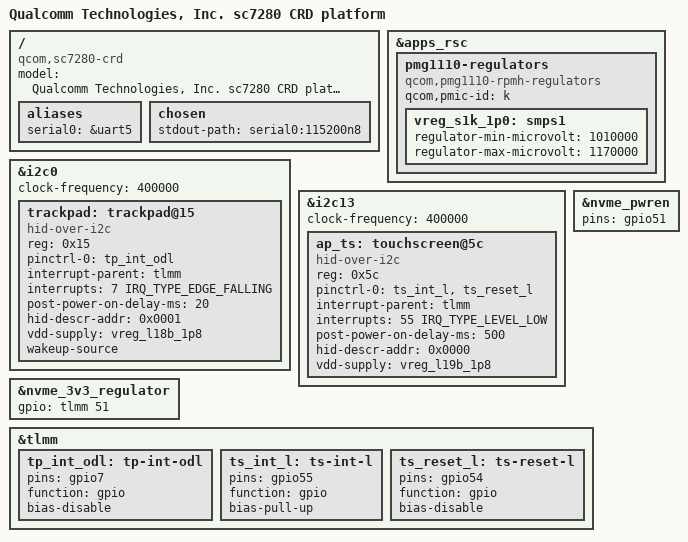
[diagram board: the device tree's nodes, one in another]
// SPDX-License-Identifier: BSD-3-Clause
/*
 * sc7280 CRD board device tree source
 *
 * Copyright (c) 2021 Qualcomm Innovation Center, Inc. All rights reserved.
 */

/dts-v1/;

#include "sc7280-idp.dtsi"
#include "sc7280-idp-ec-h1.dtsi"

/ {
	model = "Qualcomm Technologies, Inc. sc7280 CRD platform";
	compatible = "qcom,sc7280-crd", "google,hoglin", "qcom,sc7280";

	aliases {
		serial0 = &uart5;
	};

	chosen {
		stdout-path = "serial0:115200n8";
	};
};

&apps_rsc {
	pmg1110-regulators {
		compatible = "qcom,pmg1110-rpmh-regulators";
		qcom,pmic-id = "k";

		vreg_s1k_1p0: smps1 {
			regulator-min-microvolt = <1010000>;
			regulator-max-microvolt = <1170000>;
		};
	};
};

ap_tp_i2c: &i2c0 {
	status = "okay";
	clock-frequency = <400000>;

	trackpad: trackpad@15 {
		compatible = "hid-over-i2c";
		reg = <0x15>;
		pinctrl-names = "default";
		pinctrl-0 = <&tp_int_odl>;

		interrupt-parent = <&tlmm>;
		interrupts = <7 IRQ_TYPE_EDGE_FALLING>;

		post-power-on-delay-ms = <20>;
		hid-descr-addr = <0x0001>;
		vdd-supply = <&vreg_l18b_1p8>;

		wakeup-source;
	};
};

ap_ts_pen_1v8: &i2c13 {
	status = "okay";
	clock-frequency = <400000>;

	ap_ts: touchscreen@5c {
		compatible = "hid-over-i2c";
		reg = <0x5c>;
		pinctrl-names = "default";
		pinctrl-0 = <&ts_int_l>, <&ts_reset_l>;

		interrupt-parent = <&tlmm>;
		interrupts = <55 IRQ_TYPE_LEVEL_LOW>;

		post-power-on-delay-ms = <500>;
		hid-descr-addr = <0x0000>;

		vdd-supply = <&vreg_l19b_1p8>;
	};
};

&nvme_3v3_regulator {
	gpio = <&tlmm 51 GPIO_ACTIVE_HIGH>;
};

&nvme_pwren {
	pins = "gpio51";
};

&tlmm {
	tp_int_odl: tp-int-odl {
		pins = "gpio7";
		function = "gpio";
		bias-disable;
	};

	ts_int_l: ts-int-l {
		pins = "gpio55";
		function = "gpio";
		bias-pull-up;
	};

	ts_reset_l: ts-reset-l {
		pins = "gpio54";
		function = "gpio";
		bias-disable;
	};
};
